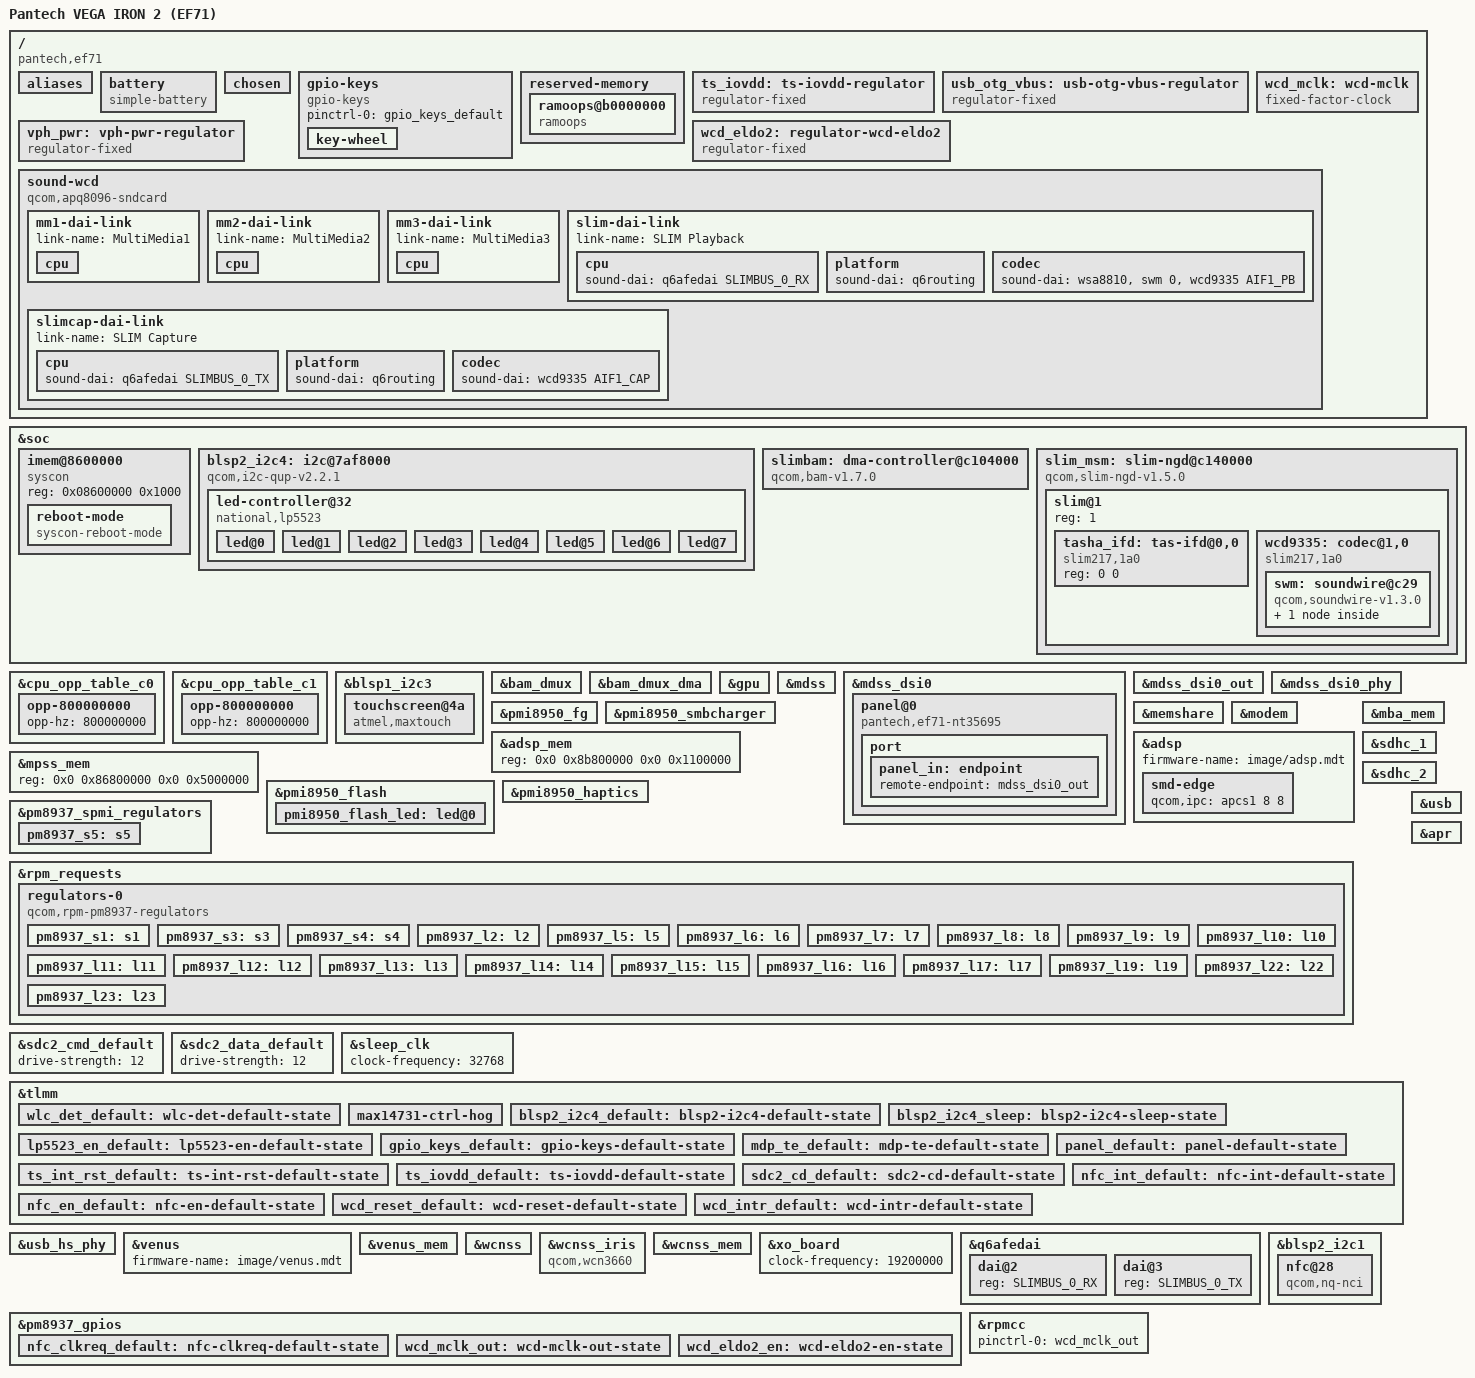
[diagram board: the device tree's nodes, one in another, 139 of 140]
// SPDX-License-Identifier: BSD-3-Clause
/*
 * Pantech VEGA IRON 2 (EF71S / IM-100S, EF71AS)
 *
 * The Pantech aboot does not read the board id from SMEM: every build
 * hardcodes the one of the revision it shipped with, and the DTB has to
 * match it exactly. List every revision of every EF71 variant
 * (S 201..206, K 211..216, G 241..246), with both subtypes.
 */
/dts-v1/;

#include <dt-bindings/arm/qcom,ids.h>
#include <dt-bindings/gpio/gpio.h>
#include <dt-bindings/input/atmel-maxtouch.h>
#include <dt-bindings/input/qcom,spmi-haptics.h>
#include <dt-bindings/leds/common.h>
#include <dt-bindings/pinctrl/qcom,pmic-gpio.h>
#include <dt-bindings/sound/qcom,q6afe.h>
#include <dt-bindings/sound/qcom,q6asm.h>
#include <dt-bindings/sound/qcom,wcd9335.h>
#include <dt-bindings/input/linux-event-codes.h>

#include "msm8937.dtsi"
#include "pm8937.dtsi"
#include "pmi8950.dtsi"

/ {
	model = "Pantech VEGA IRON 2 (EF71)";
	compatible = "pantech,ef71", "qcom,msm8937";
	chassis-type = "handset";

	qcom,msm-id = <QCOM_ID_MSM8937 0x0>;
	qcom,board-id = <201 0>, <202 0>, <203 0>, <204 0>, <205 0>, <206 0>,
			<201 1>, <202 1>, <203 1>, <204 1>, <205 1>, <206 1>,
			<211 0>, <212 0>, <213 0>, <214 0>, <215 0>, <216 0>,
			<241 0>, <242 0>, <243 0>, <244 0>, <245 0>, <246 0>;
	qcom,pmic-id = <0x10019 0x010011 0x0 0x0>;

	aliases {
		mmc0 = &sdhc_1;
		mmc1 = &sdhc_2;
	};

	/* 2950 mAh 4.4 V cell; msm-3.18 floats it at 4.42 V */
	battery: battery {
		compatible = "simple-battery";

		charge-full-design-microamp-hours = <2950000>;
		charge-term-current-microamp = <200000>;
		constant-charge-current-max-microamp = <2200000>;
		voltage-min-design-microvolt = <3400000>;
		voltage-max-design-microvolt = <4400000>;
	};

	/* aboot fails the boot when it has nowhere to put bootargs */
	chosen {
	};

	gpio-keys {
		compatible = "gpio-keys";

		pinctrl-0 = <&gpio_keys_default>;
		pinctrl-names = "default";

		/* The key under the volume wheel */
		key-wheel {
			label = "Wheel Key";
			linux,code = <KEY_MENU>;
			gpios = <&tlmm 126 GPIO_ACTIVE_LOW>;
			debounce-interval = <15>;
		};
	};

	reserved-memory {
		/* Where the msm-4.19 kernel and TWRP keep it, so TWRP reads it */
		ramoops@b0000000 {
			compatible = "ramoops";
			reg = <0x0 0xb0000000 0x0 0x800000>;
			record-size = <0x200000>;
			console-size = <0x200000>;
			pmsg-size = <0x200000>;
		};
	};

	/* Touch controller I/O supply, switched by GPIO 39 */
	ts_iovdd: ts-iovdd-regulator {
		compatible = "regulator-fixed";
		regulator-name = "ts_iovdd";
		regulator-min-microvolt = <1800000>;
		regulator-max-microvolt = <1800000>;
		gpio = <&tlmm 39 GPIO_ACTIVE_HIGH>;
		enable-active-high;
		startup-delay-us = <10000>;

		pinctrl-0 = <&ts_iovdd_default>;
		pinctrl-names = "default";
	};

	/*
	 * VBUS in host mode: the OTG boost of the PMI8950, which the MAX14731
	 * only passes to the connector while OTG_EN is high.
	 */
	usb_otg_vbus: usb-otg-vbus-regulator {
		compatible = "regulator-fixed";
		regulator-name = "usb_otg_vbus";
		regulator-min-microvolt = <5000000>;
		regulator-max-microvolt = <5000000>;
		gpio = <&tlmm 8 GPIO_ACTIVE_HIGH>;
		enable-active-high;
		vin-supply = <&otg_vbus>;
	};

	vph_pwr: vph-pwr-regulator {
		compatible = "regulator-fixed";
		regulator-name = "vph_pwr";
		regulator-min-microvolt = <3700000>;
		regulator-max-microvolt = <3700000>;
		regulator-always-on;
		regulator-boot-on;
	};
};

&soc {
	/* The restart reason aboot reads, as msm-4.19 writes it */
	imem@8600000 {
		compatible = "syscon", "simple-mfd";
		reg = <0x08600000 0x1000>;

		reboot-mode {
			compatible = "syscon-reboot-mode";
			offset = <0x65c>;
			mode-normal = <0x77665501>;
			mode-bootloader = <0x77665500>;
			mode-recovery = <0x77665502>;
		};
	};
};

/*
 * aboot hands the clusters over on GPLL0 at 800 MHz: list it, so cpufreq
 * does not have to move off it while the board comes up.
 */
&cpu_opp_table_c0 {
	opp-800000000 {
		opp-hz = /bits/ 64 <800000000>;
	};
};

&cpu_opp_table_c1 {
	opp-800000000 {
		opp-hz = /bits/ 64 <800000000>;
	};
};

&blsp1_i2c3 {
	status = "okay";

	/* EF71S: Atmel mXT641T; the EF71AS has an FT8716 on the same pins */
	touchscreen@4a {
		compatible = "atmel,maxtouch";
		reg = <0x4a>;

		interrupts-extended = <&tlmm 65 IRQ_TYPE_LEVEL_LOW>;
		reset-gpios = <&tlmm 64 GPIO_ACTIVE_LOW>;
		vdd-supply = <&ts_iovdd>;
		atmel,wakeup-method = <ATMEL_MXT_WAKEUP_I2C_SCL>;

		pinctrl-0 = <&ts_int_rst_default>;
		pinctrl-names = "default";
	};
};

&bam_dmux {
	status = "okay";
};

&bam_dmux_dma {
	status = "okay";
};

&gpu {
	status = "okay";
};

&mdss {
	status = "okay";
};

&mdss_dsi0 {
	vdda-supply = <&pm8937_l2>;
	vddio-supply = <&pm8937_l6>;

	/*
	 * The vendor T_CLK_POST: at the computed minimum the NT35695 drops
	 * the last lines of every frame and shows noise along the bottom.
	 */
	qcom,dsi-min-t-clk-post = <0x21>;

	status = "okay";

	/* EF71S; the EF71AS carries an FT8716 video mode panel instead */
	panel@0 {
		compatible = "pantech,ef71-nt35695";
		reg = <0>;

		reset-gpios = <&tlmm 60 GPIO_ACTIVE_LOW>;

		pinctrl-0 = <&panel_default &mdp_te_default>;
		pinctrl-names = "default";

		port {
			panel_in: endpoint {
				remote-endpoint = <&mdss_dsi0_out>;
			};
		};
	};
};

&mdss_dsi0_out {
	data-lanes = <0 1 2 3>;
	remote-endpoint = <&panel_in>;
};

&mdss_dsi0_phy {
	vddio-supply = <&pm8937_l6>;
	qcom,dsi-phy-regulator-ldo-mode;

	status = "okay";
};

&pmi8950_fg {
	monitored-battery = <&battery>;
	power-supplies = <&pmi8950_smbcharger>;

	status = "okay";
};

&pmi8950_smbcharger {
	monitored-battery = <&battery>;
	/* A cable takes over from the wireless pad, as on the vendor software */
	qcom,dc-yields-to-usb;
	/* The 5 W of the BQ51221 wireless receiver (vendor software: 700 mA) */
	qcom,dc-current-limit-microamp = <1000000>;

	status = "okay";
};

&memshare {
	status = "okay";
};

/*
 * Remote processor images: Android links /vendor/firmware/image, under the
 * firmware search path, to the image directory of the modem partition.
 */
&modem {
	firmware-name = "image/mba.mbn", "image/modem.mdt";
	mss-supply = <&pm8937_s1>;
	pll-supply = <&pm8937_l7>;

	status = "okay";
};

/* Where the msm-4.19 ADSP region sits */
&adsp_mem {
	reg = <0x0 0x8b800000 0x0 0x1100000>;

	status = "okay";
};

&adsp {
	firmware-name = "image/adsp.mdt";
	status = "okay";

	/*
	 * Ring the ADSP straight through the APCS IPC register: through the
	 * mailbox framework the doorbells queue up behind each other under
	 * steady APR traffic, the queue overflows and drops them, and the ADSP
	 * then stops reading the SMD FIFO, which stalls playback.
	 */
	smd-edge {
		/delete-property/ mboxes;
		qcom,ipc = <&apcs1 8 8>;
	};
};

&mba_mem {
	status = "okay";
};

/* Where the msm-4.19 modem region sits, as the modem firmware expects */
&mpss_mem {
	reg = <0x0 0x86800000 0x0 0x5000000>;

	status = "okay";
};

&pmi8950_flash {
	#address-cells = <1>;
	#size-cells = <0>;

	status = "okay";

	pmi8950_flash_led: led@0 {
		reg = <0>;
		function = LED_FUNCTION_FLASH;
		color = <LED_COLOR_ID_WHITE>;
		led-max-microamp = <200000>;
		flash-max-microamp = <1000000>;
		flash-max-timeout-us = <1280000>;
	};
};

/* EF71S: ERM motor, driven at 3.596 V as msm-4.19 does */
&pmi8950_haptics {
	qcom,actuator-type = <HAP_TYPE_ERM>;
	qcom,wave-shape = <HAP_WAVE_SQUARE>;
	qcom,wave-play-rate-us = <5263>;
	qcom,vmax-millivolt = <3596>;

	status = "okay";
};

&pm8937_spmi_regulators {
	/* APC */
	pm8937_s5: s5 {
		regulator-min-microvolt = <1050000>;
		regulator-max-microvolt = <1350000>;
		regulator-always-on;
		regulator-boot-on;
	};
};

&rpm_requests {
	regulators-0 {
		compatible = "qcom,rpm-pm8937-regulators";

		vdd_s1-supply = <&vph_pwr>;
		vdd_s2-supply = <&vph_pwr>;
		vdd_s3-supply = <&vph_pwr>;
		vdd_s4-supply = <&vph_pwr>;

		vdd_l1_l19-supply = <&pm8937_s3>;
		vdd_l2_l23-supply = <&pm8937_s3>;
		vdd_l3-supply = <&pm8937_s3>;
		vdd_l4_l5_l6_l7_l16-supply = <&pm8937_s4>;
		vdd_l8_l11_l12_l17_l22-supply = <&vph_pwr>;
		vdd_l9_l10_l13_l14_l15_l18-supply = <&vph_pwr>;

		pm8937_s1: s1 {
			regulator-min-microvolt = <1000000>;
			regulator-max-microvolt = <1225000>;
		};

		pm8937_s3: s3 {
			regulator-min-microvolt = <1300000>;
			regulator-max-microvolt = <1300000>;
		};

		pm8937_s4: s4 {
			regulator-min-microvolt = <2050000>;
			regulator-max-microvolt = <2050000>;
		};

		pm8937_l2: l2 {
			regulator-min-microvolt = <1200000>;
			regulator-max-microvolt = <1200000>;
		};

		pm8937_l5: l5 {
			regulator-min-microvolt = <1800000>;
			regulator-max-microvolt = <1800000>;
		};

		pm8937_l6: l6 {
			regulator-min-microvolt = <1800000>;
			regulator-max-microvolt = <1800000>;
		};

		pm8937_l7: l7 {
			regulator-min-microvolt = <1800000>;
			regulator-max-microvolt = <1800000>;
		};

		pm8937_l8: l8 {
			regulator-min-microvolt = <2850000>;
			regulator-max-microvolt = <2900000>;
		};

		pm8937_l9: l9 {
			regulator-min-microvolt = <3000000>;
			regulator-max-microvolt = <3300000>;
		};

		pm8937_l10: l10 {
			regulator-min-microvolt = <2800000>;
			regulator-max-microvolt = <3000000>;
		};

		pm8937_l11: l11 {
			regulator-min-microvolt = <2950000>;
			regulator-max-microvolt = <2950000>;
			regulator-allow-set-load;
			regulator-system-load = <200000>;
		};

		pm8937_l12: l12 {
			regulator-min-microvolt = <1800000>;
			regulator-max-microvolt = <2950000>;
		};

		pm8937_l13: l13 {
			regulator-min-microvolt = <3075000>;
			regulator-max-microvolt = <3075000>;
			/*
			 * Powers the USB PHY, whose D+ and D- otherwise clamp
			 * near 0.6V: an HVDCP adapter then takes the request
			 * for 9V for one for 12V. The vendor kernel kept it on
			 * while a charger was attached.
			 */
			regulator-always-on;
		};

		pm8937_l14: l14 {
			regulator-min-microvolt = <1800000>;
			regulator-max-microvolt = <3300000>;
		};

		pm8937_l15: l15 {
			regulator-min-microvolt = <1800000>;
			regulator-max-microvolt = <3300000>;
		};

		pm8937_l16: l16 {
			regulator-min-microvolt = <1800000>;
			regulator-max-microvolt = <1800000>;
		};

		pm8937_l17: l17 {
			regulator-min-microvolt = <2800000>;
			regulator-max-microvolt = <2900000>;
		};

		pm8937_l19: l19 {
			regulator-min-microvolt = <1225000>;
			regulator-max-microvolt = <1350000>;
		};

		pm8937_l22: l22 {
			regulator-min-microvolt = <2800000>;
			regulator-max-microvolt = <2800000>;
		};

		pm8937_l23: l23 {
			regulator-min-microvolt = <1200000>;
			regulator-max-microvolt = <1200000>;
		};
	};
};

&sdc2_cmd_default {
	drive-strength = <12>;
};

&sdc2_data_default {
	drive-strength = <12>;
};

&sdhc_1 {
	vmmc-supply = <&pm8937_l8>;
	vqmmc-supply = <&pm8937_l5>;

	status = "okay";
};

&sdhc_2 {
	cd-gpios = <&tlmm 67 GPIO_ACTIVE_LOW>;
	vmmc-supply = <&pm8937_l11>;
	vqmmc-supply = <&pm8937_l12>;
	pinctrl-0 = <&sdc2_default &sdc2_cd_default>;
	pinctrl-1 = <&sdc2_sleep &sdc2_cd_default>;
	pinctrl-names = "default", "sleep";

	status = "okay";
};

&sleep_clk {
	clock-frequency = <32768>;
};

/*
 * BLSP2 QUP4, absent from msm8937.dtsi, carries the LP5523 that drives the
 * front indicator, a left and a right RGB LED, and the menu and back key
 * backlights. Channel 8 only took the commands of the Pantech driver.
 */
&soc {
	blsp2_i2c4: i2c@7af8000 {
		compatible = "qcom,i2c-qup-v2.2.1";
		reg = <0x07af8000 0x600>;
		interrupts = <GIC_SPI 302 IRQ_TYPE_LEVEL_HIGH>;
		clocks = <&gcc MSM8937_GCC_BLSP2_QUP4_I2C_APPS_CLK>,
			 <&gcc GCC_BLSP2_AHB_CLK>;
		clock-names = "core",
			      "iface";
		dmas = <&blsp2_dma 10>,
		       <&blsp2_dma 11>;
		dma-names = "tx",
			    "rx";
		pinctrl-0 = <&blsp2_i2c4_default>;
		pinctrl-1 = <&blsp2_i2c4_sleep>;
		pinctrl-names = "default",
				"sleep";
		#address-cells = <1>;
		#size-cells = <0>;

		led-controller@32 {
			compatible = "national,lp5523";
			reg = <0x32>;
			clock-mode = /bits/ 8 <1>;
			enable-gpios = <&tlmm 129 GPIO_ACTIVE_HIGH>;
			pinctrl-0 = <&lp5523_en_default>;
			pinctrl-names = "default";
			#address-cells = <1>;
			#size-cells = <0>;

			led@0 {
				reg = <0>;
				chan-name = "lp5523:channel0";
				color = <LED_COLOR_ID_GREEN>;
				led-cur = /bits/ 8 <40>;
				max-cur = /bits/ 8 <250>;
			};

			led@1 {
				reg = <1>;
				chan-name = "lp5523:channel1";
				color = <LED_COLOR_ID_BLUE>;
				led-cur = /bits/ 8 <40>;
				max-cur = /bits/ 8 <250>;
			};

			led@2 {
				reg = <2>;
				chan-name = "lp5523:channel2";
				color = <LED_COLOR_ID_GREEN>;
				led-cur = /bits/ 8 <40>;
				max-cur = /bits/ 8 <250>;
			};

			led@3 {
				reg = <3>;
				chan-name = "lp5523:channel3";
				color = <LED_COLOR_ID_BLUE>;
				led-cur = /bits/ 8 <40>;
				max-cur = /bits/ 8 <250>;
			};

			led@4 {
				reg = <4>;
				chan-name = "lp5523:channel4";
				color = <LED_COLOR_ID_WHITE>;
				led-cur = /bits/ 8 <40>;
				max-cur = /bits/ 8 <250>;
			};

			led@5 {
				reg = <5>;
				chan-name = "lp5523:channel5";
				color = <LED_COLOR_ID_WHITE>;
				led-cur = /bits/ 8 <40>;
				max-cur = /bits/ 8 <250>;
			};

			led@6 {
				reg = <6>;
				chan-name = "lp5523:channel6";
				color = <LED_COLOR_ID_RED>;
				led-cur = /bits/ 8 <40>;
				max-cur = /bits/ 8 <250>;
			};

			led@7 {
				reg = <7>;
				chan-name = "lp5523:channel7";
				color = <LED_COLOR_ID_RED>;
				led-cur = /bits/ 8 <40>;
				max-cur = /bits/ 8 <250>;
			};
		};
	};
};

&tlmm {
	/* GPIO 0 switches the front camera supply, as on msm-4.19 */
	gpio-reserved-ranges = <1 3>, <20 4>;

	pinctrl-0 = <&wlc_det_default>;
	pinctrl-names = "default";

	/*
	 * Detect lines of the BQ51221 wireless receiver and the MAX14731
	 * (WL_PG, WLC_DET_N, WL_PAD_DET, USB_VBUS_DET_N), set up as the
	 * vendor software does.
	 */
	wlc_det_default: wlc-det-default-state {
		pins = "gpio12", "gpio61", "gpio62", "gpio63";
		function = "gpio";
		drive-strength = <6>;
		bias-pull-up;
	};

	/*
	 * The MAX14731 in front of USBIN and the DCIN of the BQ51221 wireless
	 * receiver: the vendor driver holds OVP_EN_N and P-CONNECT low as
	 * outputs, without which the wireless input stays cut off. OTG_EN goes
	 * with the OTG VBUS regulator.
	 */
	max14731-ctrl-hog {
		gpio-hog;
		gpios = <59 GPIO_ACTIVE_HIGH>, <125 GPIO_ACTIVE_HIGH>;
		output-low;
		line-name = "max14731-ctrl";
	};

	blsp2_i2c4_default: blsp2-i2c4-default-state {
		pins = "gpio98", "gpio99";
		function = "blsp_i2c8";
		drive-strength = <2>;
		bias-disable;
	};

	blsp2_i2c4_sleep: blsp2-i2c4-sleep-state {
		pins = "gpio98", "gpio99";
		function = "gpio";
		drive-strength = <2>;
		bias-disable;
	};

	lp5523_en_default: lp5523-en-default-state {
		pins = "gpio129";
		function = "gpio";
		drive-strength = <2>;
		bias-disable;
	};

	gpio_keys_default: gpio-keys-default-state {
		pins = "gpio126";
		function = "gpio";
		drive-strength = <2>;
		bias-pull-up;
	};

	mdp_te_default: mdp-te-default-state {
		pins = "gpio24";
		function = "mdp_vsync";
		drive-strength = <2>;
		bias-pull-down;
	};

	panel_default: panel-default-state {
		pins = "gpio60";
		function = "gpio";
		drive-strength = <8>;
		bias-disable;
	};

	ts_int_rst_default: ts-int-rst-default-state {
		pins = "gpio64", "gpio65";
		function = "gpio";
		drive-strength = <8>;
		bias-pull-up;
	};

	ts_iovdd_default: ts-iovdd-default-state {
		pins = "gpio39";
		function = "gpio";
		drive-strength = <2>;
		bias-disable;
	};

	sdc2_cd_default: sdc2-cd-default-state {
		pins = "gpio67";
		function = "gpio";
		drive-strength = <2>;
		bias-disable;
	};
};

&usb {
	dr_mode = "otg";
	extcon = <&pmi8950_smbcharger>, <&pmi8950_smbcharger>;
	vbus-supply = <&usb_otg_vbus>;

	status = "okay";
};

&usb_hs_phy {
	vdd-supply = <&pm8937_l2>;
	vdda1p8-supply = <&pm8937_l7>;
	vdda3p3-supply = <&pm8937_l13>;

	status = "okay";
};

&venus {
	firmware-name = "image/venus.mdt";

	status = "okay";
};

&venus_mem {
	status = "okay";
};

&wcnss {
	firmware-name = "image/wcnss.mdt";
	vddpx-supply = <&pm8937_l5>;

	status = "okay";
};

/* IRIS 0x0400: WCN3660, dual band */
&wcnss_iris {
	compatible = "qcom,wcn3660";
	vddxo-supply = <&pm8937_l7>;
	vddrfa-supply = <&pm8937_l19>;
	vddpa-supply = <&pm8937_l9>;
	vdddig-supply = <&pm8937_l5>;
};

&wcnss_mem {
	status = "okay";
};

&xo_board {
	clock-frequency = <19200000>;
};

/*
 * Audio: WCD9335 (Tasha) on the SLIMbus of the ADSP, as on the OnePlus 3
 * (MSM8996). Wiring from the msm-4.19 EF71 tree: reset on GPIO 68,
 * interrupt on GPIO 73, MCLK as the 9.6 MHz RPM DIV_CLK2 out of PM8937
 * GPIO 1, 1.8 V buck supply switched by PM8937 GPIO 7.
 */
/ {
	wcd_mclk: wcd-mclk {
		compatible = "fixed-factor-clock";
		clocks = <&rpmcc RPM_SMD_DIV_CLK2>;
		clock-div = <2>;
		clock-mult = <1>;
		#clock-cells = <0>;
		clock-output-names = "wcd_mclk";
	};

	wcd_eldo2: regulator-wcd-eldo2 {
		compatible = "regulator-fixed";
		regulator-name = "wcd_eldo2";
		regulator-min-microvolt = <1800000>;
		regulator-max-microvolt = <1800000>;
		gpio = <&pm8937_gpios 7 GPIO_ACTIVE_HIGH>;
		enable-active-high;
		pinctrl-0 = <&wcd_eldo2_en>;
		pinctrl-names = "default";
	};

	sound-wcd {
		compatible = "qcom,apq8096-sndcard";
		model = "ef71-tasha";
		widgets = "Microphone", "Handset Mic",
			  "Microphone", "Headset Mic",
			  "Microphone", "Secondary Mic",
			  "Speaker", "Loudspeaker";
		audio-routing = "RX_BIAS", "MCLK",
				"SpkrLeft IN", "SPK1 OUT",
				"Loudspeaker", "SpkrLeft SPKR",
				"ADC2", "MCLK",
				"ADC3", "MCLK",
				"ADC4", "MCLK",
				"AMIC2", "MIC BIAS2",
				"AMIC2", "Headset Mic",
				"AMIC3", "MIC BIAS1",
				"AMIC3", "Handset Mic",
				"AMIC4", "MIC BIAS3",
				"AMIC4", "Secondary Mic";

		mm1-dai-link {
			link-name = "MultiMedia1";

			cpu {
				sound-dai = <&q6asmdai MSM_FRONTEND_DAI_MULTIMEDIA1>;
			};
		};

		mm2-dai-link {
			link-name = "MultiMedia2";

			cpu {
				sound-dai = <&q6asmdai MSM_FRONTEND_DAI_MULTIMEDIA2>;
			};
		};

		mm3-dai-link {
			link-name = "MultiMedia3";

			cpu {
				sound-dai = <&q6asmdai MSM_FRONTEND_DAI_MULTIMEDIA3>;
			};
		};

		slim-dai-link {
			link-name = "SLIM Playback";

			cpu {
				sound-dai = <&q6afedai SLIMBUS_0_RX>;
			};

			platform {
				sound-dai = <&q6routing>;
			};

			codec {
				/* Amplifier first: the master allocates its ports */
				sound-dai = <&wsa8810>,
					    <&swm 0>,
					    <&wcd9335 AIF1_PB>;
			};
		};

		slimcap-dai-link {
			link-name = "SLIM Capture";

			cpu {
				sound-dai = <&q6afedai SLIMBUS_0_TX>;
			};

			platform {
				sound-dai = <&q6routing>;
			};

			codec {
				sound-dai = <&wcd9335 AIF1_CAP>;
			};
		};
	};
};

&soc {
	slimbam: dma-controller@c104000 {
		compatible = "qcom,bam-v1.7.0";
		qcom,controlled-remotely;
		reg = <0x0c104000 0x2a000>;
		num-channels = <23>;
		interrupts = <GIC_SPI 180 IRQ_TYPE_LEVEL_HIGH>;
		#dma-cells = <1>;
		qcom,ee = <1>;
		qcom,num-ees = <2>;
	};

	slim_msm: slim-ngd@c140000 {
		compatible = "qcom,slim-ngd-v1.5.0";
		reg = <0x0c140000 0x2c000>;
		interrupts = <GIC_SPI 163 IRQ_TYPE_LEVEL_HIGH>;
		dmas = <&slimbam 3>, <&slimbam 4>;
		dma-names = "rx", "tx";
		#address-cells = <1>;
		#size-cells = <0>;

		slim@1 {
			reg = <1>;
			#address-cells = <2>;
			#size-cells = <0>;

			tasha_ifd: tas-ifd@0,0 {
				compatible = "slim217,1a0";
				reg = <0 0>;
			};

			wcd9335: codec@1,0 {
				compatible = "slim217,1a0";
				reg = <1 0>;

				clock-names = "mclk", "slimbus";
				clocks = <&wcd_mclk>,
					 <&rpmcc RPM_SMD_BB_CLK1>;
				interrupt-parent = <&tlmm>;
				interrupts = <73 IRQ_TYPE_LEVEL_HIGH>;
				interrupt-names = "intr1";
				interrupt-controller;
				#interrupt-cells = <1>;

				pinctrl-0 = <&wcd_reset_default &wcd_intr_default>;
				pinctrl-names = "default";

				reset-gpios = <&tlmm 68 GPIO_ACTIVE_LOW>;
				slim-ifc-dev = <&tasha_ifd>;

				#sound-dai-cells = <1>;

				vdd-buck-supply = <&wcd_eldo2>;
				vdd-buck-sido-supply = <&wcd_eldo2>;
				vdd-tx-supply = <&pm8937_l5>;
				vdd-rx-supply = <&pm8937_l5>;
				vdd-io-supply = <&pm8937_l5>;

				#clock-cells = <0>;
				#address-cells = <1>;
				#size-cells = <1>;

				/* The loudspeaker amplifier hangs off this master */
				swm: soundwire@c29 {
					compatible = "qcom,soundwire-v1.3.0";
					reg = <0xc29 0x12>;
					interrupts-extended = <&wcd9335 20>;

					qcom,dout-ports = <6>;
					qcom,din-ports = <2>;
					qcom,ports-sinterval-low = /bits/ 8 <0x07 0x1f 0x3f 0x07 0x1f 0x3f 0x0f 0x0f>;
					qcom,ports-offset1 = /bits/ 8 <0x01 0x02 0x0c 0x06 0x12 0x0d 0x07 0x0a>;
					qcom,ports-offset2 = /bits/ 8 <0x00 0x00 0x1f 0x00 0x00 0x1f 0x00 0x00>;

					clocks = <&wcd9335>;
					clock-names = "iface";

					#sound-dai-cells = <1>;
					#address-cells = <2>;
					#size-cells = <0>;

					wsa8810: speaker@0,1 {
						compatible = "sdw10217201000";
						reg = <0 1>;
						/* SD_N: low shuts the amplifier down */
						powerdown-gpios = <&tlmm 96 GPIO_ACTIVE_LOW>;
						sound-name-prefix = "SpkrLeft";
						#sound-dai-cells = <0>;
					};
				};
			};
		};
	};
};

&apr {
	status = "okay";
};

&q6afedai {
	dai@2 {
		reg = <SLIMBUS_0_RX>;
	};

	dai@3 {
		reg = <SLIMBUS_0_TX>;
	};
};

/*
 * PN548 NFC controller, driven by the nq-nci char driver the Android NFC
 * HAL opens as /dev/nq-nci. BB_CLK2 runs in pin control mode and follows
 * the controller's clock request on PM8937 GPIO 5, so that pin has to be
 * set up as an input or the PN548 resets as soon as it turns its field on.
 */
&blsp2_i2c1 {
	status = "okay";

	nfc@28 {
		compatible = "qcom,nq-nci";
		reg = <0x28>;

		interrupts-extended = <&tlmm 17 IRQ_TYPE_LEVEL_HIGH>;
		interrupt-names = "nfc_irq";

		qcom,nq-irq-gpios = <&tlmm 17 GPIO_ACTIVE_HIGH>;
		qcom,nq-ven-gpios = <&tlmm 16 GPIO_ACTIVE_HIGH>;
		qcom,nq-firm-gpios = <&tlmm 130 GPIO_ACTIVE_HIGH>;
		qcom,nq-clkreq-gpios = <&pm8937_gpios 5 GPIO_ACTIVE_HIGH>;
		qcom,clk-src = "BBCLK2";

		clocks = <&rpmcc RPM_SMD_BB_CLK2_PIN>;
		clock-names = "ref_clk";

		pinctrl-0 = <&nfc_int_default &nfc_en_default &nfc_clkreq_default>;
		pinctrl-names = "default";
	};
};

&pm8937_gpios {
	nfc_clkreq_default: nfc-clkreq-default-state {
		pins = "gpio5";
		function = PMIC_GPIO_FUNC_NORMAL;
		input-enable;
		power-source = <1>;
	};

	wcd_mclk_out: wcd-mclk-out-state {
		pins = "gpio1";
		function = PMIC_GPIO_FUNC_FUNC1;
		output-low;
		bias-disable;
		power-source = <0>;
		qcom,drive-strength = <PMIC_GPIO_STRENGTH_LOW>;
	};

	wcd_eldo2_en: wcd-eldo2-en-state {
		pins = "gpio7";
		function = PMIC_GPIO_FUNC_NORMAL;
		bias-disable;
		power-source = <0>;
	};
};

&rpmcc {
	pinctrl-0 = <&wcd_mclk_out>;
	pinctrl-names = "default";
};

&tlmm {
	nfc_int_default: nfc-int-default-state {
		pins = "gpio17";
		function = "gpio";
		drive-strength = <6>;
		bias-pull-down;
	};

	nfc_en_default: nfc-en-default-state {
		pins = "gpio16", "gpio130";
		function = "gpio";
		drive-strength = <6>;
		bias-pull-down;
	};

	wcd_reset_default: wcd-reset-default-state {
		pins = "gpio68";
		function = "gpio";
		drive-strength = <16>;
		bias-disable;
		output-high;
	};

	wcd_intr_default: wcd-intr-default-state {
		pins = "gpio73";
		function = "gpio";
		drive-strength = <2>;
		bias-pull-down;
		input-enable;
	};
};

#include "msm8937-pantech-ef71-camera.dtsi"
